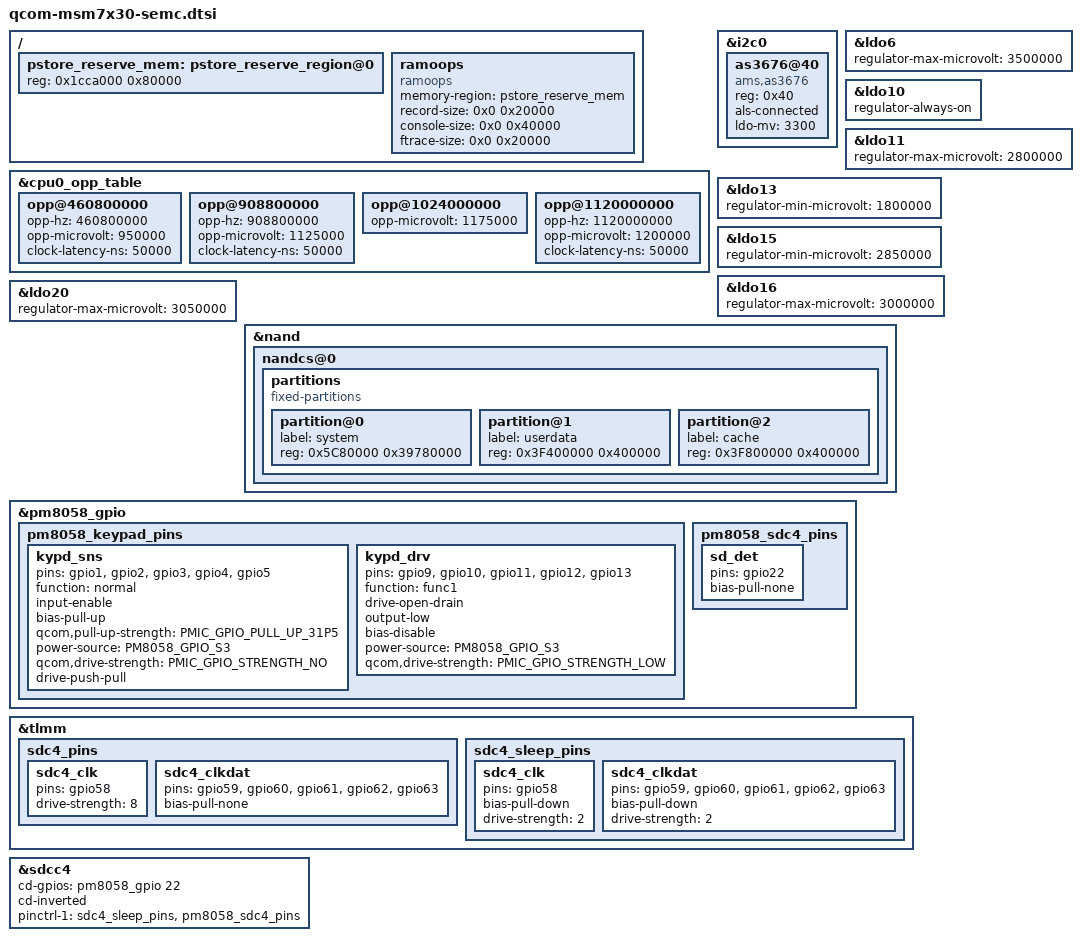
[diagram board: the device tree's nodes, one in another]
#include "qcom-msm7x30.dtsi"

/ {
	pstore_reserve_mem: pstore_reserve_region@0 {
		reg = <0x1cca000 0x80000>;
		reg-names = "ramoops_mem";
	};

	ramoops {
		compatible = "ramoops";
		memory-region = <&pstore_reserve_mem>;
		record-size = <0x0 0x20000>;
		console-size = <0x0 0x40000>;
		ftrace-size = <0x0 0x20000>;
	};
};

&cpu0_opp_table {
	/delete-node/ opp@24576000;
	/delete-node/ opp@61440000;

	opp@460800000 {
		opp-hz = /bits/ 64 <460800000>;
		opp-microvolt = <950000>;
		clock-latency-ns = <50000>;
	};
	opp@908800000 {
		opp-hz = /bits/ 64 <908800000>;
		opp-microvolt = <1125000>;
		clock-latency-ns = <50000>;
	};
	opp@1024000000 {
		opp-microvolt = <1175000>;
	};
	opp@1120000000 {
		opp-hz = /bits/ 64 <1120000000>;
		opp-microvolt = <1200000>;
		clock-latency-ns = <50000>;
	};
};

&i2c0 {
	as3676@40 {
		compatible = "ams,as3676";
		reg = <0x40>;

		als-connected;
		ldo-mv = <3300>;
	};
};

&ldo6 {
	regulator-max-microvolt = <3500000>;
};

&ldo10 {
	regulator-always-on;
};

&ldo11 {
	regulator-max-microvolt = <2800000>;
};

&ldo13 {
	regulator-min-microvolt = <1800000>;
};

&ldo15 {
	regulator-min-microvolt = <2850000>;
};

&ldo16 {
	regulator-max-microvolt = <3000000>;
};

&ldo20 {
	regulator-max-microvolt = <3050000>;
};

&nand {
	status = "ok";
	nandcs@0 {
		partitions {
			compatible = "fixed-partitions";
			#address-cells = <1>;
			#size-cells = <1>;

			partition@0 {
				label= "system";
				reg = <0x5C80000 0x39780000>;
			};
			partition@1 {
				label= "userdata";
				reg = <0x3F400000 0x400000>;
			};
			partition@2 {
				label= "cache";
				reg = <0x3F800000 0x400000>;
			};
		};
	};

};

&pm8058_gpio {
	pm8058_keypad_pins: pm8058_keypad_pins {
		kypd_sns {
			pins = "gpio1", "gpio2", "gpio3", "gpio4", "gpio5";
			function = "normal";
			input-enable;
			bias-pull-up;
			qcom,pull-up-strength = <PMIC_GPIO_PULL_UP_31P5>;
			power-source = <PM8058_GPIO_S3>;
			qcom,drive-strength = <PMIC_GPIO_STRENGTH_NO>;
			drive-push-pull;
		};

		kypd_drv {
			pins = "gpio9", "gpio10", "gpio11", "gpio12", "gpio13";
			function = "func1";
			drive-open-drain;
			output-low;
			bias-disable;
			power-source = <PM8058_GPIO_S3>;
			qcom,drive-strength = <PMIC_GPIO_STRENGTH_LOW>;
		};
	};

	pm8058_sdc4_pins: pm8058_sdc4_pins {
		sd_det {
			pins = "gpio22";
			bias-pull-none;
			/delete-property/ qcom,pull-up-strength;
		};
	};
};

&tlmm {
	sdc4_pins: sdc4_pins {
		sdc4_clk {
			pins = "gpio58";
			drive-strength = <8>;
		};

		sdc4_clkdat {
			pins = "gpio59", "gpio60", "gpio61", "gpio62", "gpio63";
			bias-pull-none;
		};
	};

	sdc4_sleep_pins: sdc4_sleep_pins {
		sdc4_clk {
			pins = "gpio58";
			bias-pull-down;
			drive-strength = <2>;
		};

		sdc4_clkdat {
			pins = "gpio59", "gpio60", "gpio61", "gpio62", "gpio63";
			bias-pull-down;
			drive-strength = <2>;
		};
	};
};

/* External micro SD card */
&sdcc4 {
	status = "ok";
	cd-gpios = <&pm8058_gpio 22 0>;
	cd-inverted;

	pinctrl-names	= "default", "sleep";
	pinctrl-1	= <&sdc4_sleep_pins>,
			  <&pm8058_sdc4_pins>;
};
